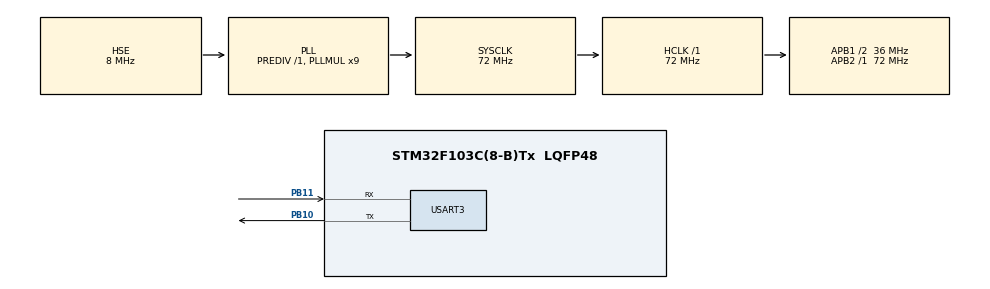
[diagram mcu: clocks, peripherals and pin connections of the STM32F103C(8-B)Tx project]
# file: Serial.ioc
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Mcu.Family=STM32F1
Mcu.Name=STM32F103C(8-B)Tx
Mcu.Package=LQFP48
NVIC.PriorityGroup=NVIC_PRIORITYGROUP_4
NVIC.USART3_IRQn=true\:0\:0\:false\:false\:true\:true\:true\:true
PA13.Mode=Serial_Wire
PA13.Signal=SYS_JTMS-SWDIO
PA14.Mode=Serial_Wire
PA14.Signal=SYS_JTCK-SWCLK
PB10.Mode=Asynchronous
PB10.Signal=USART3_TX
PB11.Mode=Asynchronous
PB11.Signal=USART3_RX
PD0-OSC_IN.Mode=HSE-External-Oscillator
PD0-OSC_IN.Signal=RCC_OSC_IN
PD1-OSC_OUT.Mode=HSE-External-Oscillator
PD1-OSC_OUT.Signal=RCC_OSC_OUT
ProjectManager.HeapSize=0x200
ProjectManager.StackSize=0x400
ProjectManager.TargetToolchain=CMake
RCC.AHBFreq_Value=72000000
RCC.APB1CLKDivider=RCC_HCLK_DIV2
RCC.APB1Freq_Value=36000000
RCC.APB1TimFreq_Value=72000000
RCC.APB2Freq_Value=72000000
RCC.APB2TimFreq_Value=72000000
RCC.HCLKFreq_Value=72000000
RCC.PLLMUL=RCC_PLL_MUL9
RCC.PLLSourceVirtual=RCC_PLLSOURCE_HSE
RCC.SYSCLKFreq_VALUE=72000000
RCC.SYSCLKSource=RCC_SYSCLKSOURCE_PLLCLK
RCC.USBFreq_Value=72000000
USART3.VirtualMode=VM_ASYNC
board=custom

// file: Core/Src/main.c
/* USER CODE BEGIN Header */
/**
  ******************************************************************************
  * @file           : main.c
  * @brief          : Main program body
  ******************************************************************************
  * @attention
  *
  * Copyright (c) 2026 STMicroelectronics.
  * All rights reserved.
  *
  * This software is licensed under terms that can be found in the LICENSE file
  * in the root directory of this software component.
  * If no LICENSE file comes with this software, it is provided AS-IS.
  *
  ******************************************************************************
  */
/* USER CODE END Header */
#include "main.h"
#include "usart.h"
#include "gpio.h"

/* USER CODE BEGIN Includes */
#include <stdio.h>
#include <string.h>
/* USER CODE END Includes */

/* USER CODE BEGIN PD */
#define RX_BUF_SIZE  64
/* USER CODE END PD */

/* USER CODE BEGIN PV */
uint8_t rx_buffer[RX_BUF_SIZE];
uint8_t rx_byte;
volatile uint8_t rx_complete = 0;
volatile uint8_t rx_index = 0;
/* USER CODE END PV */

void SystemClock_Config(void);

/* USER CODE BEGIN 0 */

// 串口接收回调函数（当收到一个字节时触发）
void HAL_UART_RxCpltCallback(UART_HandleTypeDef *huart)
{
    if (huart->Instance == USART3)
    {
        // 将接收到的字节存入缓冲区
        if (rx_index < RX_BUF_SIZE - 1)
        {
            rx_buffer[rx_index++] = rx_byte;
            // 如果收到换行符（\n 或 \r），认为一行结束
            if (rx_byte == '\n' || rx_byte == '\r')
            {
                rx_buffer[rx_index] = '\0';   // 添加字符串结束符
                rx_complete = 1;              // 标记收到完整一行
            }
        }
        // 继续接收下一个字节
        HAL_UART_Receive_IT(&huart3, &rx_byte, 1);
    }
}

/* USER CODE END 0 */

int main(void)
{

  /* MCU Configuration--------------------------------------------------------*/

  /* Reset of all peripherals, Initializes the Flash interface and the Systick. */
  HAL_Init();

  /* Configure the system clock */
  SystemClock_Config();

  /* Initialize all configured peripherals */
  MX_GPIO_Init();
  MX_USART3_UART_Init();
  /* USER CODE BEGIN 2 */
  // 启动串口接收中断（接收一个字节）
  HAL_UART_Receive_IT(&huart3, &rx_byte, 1);

  printf("System ready!\r\n");
  /* USER CODE END 2 */

  /* Infinite loop */
  /* USER CODE BEGIN WHILE */
  uint32_t last_send_time = 0;
  while (1)
  {
    // 每秒发送一次欢迎消息
    if (HAL_GetTick() - last_send_time >= 1000)
    {
        last_send_time = HAL_GetTick();
        printf("Welcome to the world of embedded systems！\r\n");
    }

    // 检查是否收到完整的一行
    if (rx_complete)
    {
        rx_complete = 0;
        // 回显收到的消息（用printf）
        printf("Received: %s", rx_buffer);
        // 清空缓冲区
        rx_index = 0;
        memset(rx_buffer, 0, RX_BUF_SIZE);
    }

    /* USER CODE END WHILE */

  }
}

void SystemClock_Config(void)
{
  RCC_OscInitTypeDef RCC_OscInitStruct = {0};
  RCC_ClkInitTypeDef RCC_ClkInitStruct = {0};

  /** Initializes the RCC Oscillators according to the specified parameters
  * in the RCC_OscInitTypeDef structure.
  */
  RCC_OscInitStruct.OscillatorType = RCC_OSCILLATORTYPE_HSE;
  RCC_OscInitStruct.HSEState = RCC_HSE_ON;
  RCC_OscInitStruct.HSEPredivValue = RCC_HSE_PREDIV_DIV1;
  RCC_OscInitStruct.HSIState = RCC_HSI_ON;
  RCC_OscInitStruct.PLL.PLLState = RCC_PLL_ON;
  RCC_OscInitStruct.PLL.PLLSource = RCC_PLLSOURCE_HSE;
  RCC_OscInitStruct.PLL.PLLMUL = RCC_PLL_MUL9;
  if (HAL_RCC_OscConfig(&RCC_OscInitStruct) != HAL_OK)
  {
    Error_Handler();
  }

  /** Initializes the CPU, AHB and APB buses clocks
  */
  RCC_ClkInitStruct.ClockType = RCC_CLOCKTYPE_HCLK|RCC_CLOCKTYPE_SYSCLK
                              |RCC_CLOCKTYPE_PCLK1|RCC_CLOCKTYPE_PCLK2;
  RCC_ClkInitStruct.SYSCLKSource = RCC_SYSCLKSOURCE_PLLCLK;
  RCC_ClkInitStruct.AHBCLKDivider = RCC_SYSCLK_DIV1;
  RCC_ClkInitStruct.APB1CLKDivider = RCC_HCLK_DIV2;
  RCC_ClkInitStruct.APB2CLKDivider = RCC_HCLK_DIV1;

  if (HAL_RCC_ClockConfig(&RCC_ClkInitStruct, FLASH_LATENCY_2) != HAL_OK)
  {
    Error_Handler();
  }
}

void Error_Handler(void)
{
  __disable_irq();
  while (1)
  {
  }
}
